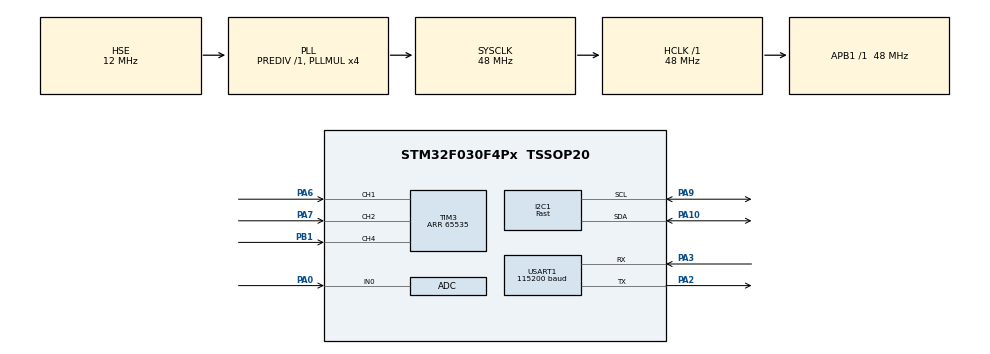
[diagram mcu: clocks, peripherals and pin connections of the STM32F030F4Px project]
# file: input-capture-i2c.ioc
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ADC.SamplingTime=ADC_SAMPLETIME_239CYCLES_5
I2C1.I2C_Speed_Mode=I2C_Fast
I2C1.OwnAddress=4
I2C1.Timing=0x2010091A
Mcu.Family=STM32F0
Mcu.Name=STM32F030F4Px
Mcu.Package=TSSOP20
NVIC.ADC1_IRQn=true\:3\:0\:true\:false\:true
NVIC.I2C1_IRQn=true\:2\:0\:true\:false\:true
NVIC.TIM1_BRK_UP_TRG_COM_IRQn=true\:2\:0\:true\:false\:true
NVIC.TIM3_IRQn=true\:0\:0\:false\:false\:true
NVIC.USART1_IRQn=true\:3\:0\:true\:false\:true
PA0.Mode=IN0
PA0.Signal=ADC_IN0
PA10.GPIO_PuPdOD=GPIO_PULLUP
PA10.Mode=I2C
PA10.Signal=I2C1_SDA
PA13.Mode=Serial_Wire
PA13.Signal=SYS_SWDIO
PA14.Mode=Serial_Wire
PA14.Signal=SYS_SWCLK
PA2.Mode=Asynchronous
PA2.Signal=USART1_TX
PA3.Mode=Asynchronous
PA3.Signal=USART1_RX
PA6.Signal=S_TIM3_CH1
PA7.Signal=S_TIM3_CH2
PA9.GPIO_PuPdOD=GPIO_PULLUP
PA9.Mode=I2C
PA9.Signal=I2C1_SCL
PB1.Signal=S_TIM3_CH4
PF0-OSC_IN.Mode=HSE-External-Clock-Source
PF0-OSC_IN.Signal=RCC_OSC_IN
ProjectManager.HeapSize=0x200
ProjectManager.StackSize=0x400
ProjectManager.TargetToolchain=SW4STM32
RCC.AHBFreq_Value=48000000
RCC.APB1Freq_Value=48000000
RCC.APB1TimFreq_Value=48000000
RCC.HCLKFreq_Value=48000000
RCC.HSE_VALUE=12000000
RCC.HSIState=RCC_HSI_ON
RCC.I2c1ClockSelection=RCC_I2C1CLKSOURCE_SYSCLK
RCC.PLLMUL=RCC_PLL_MUL4
RCC.PLLSourceVirtual=RCC_PLLSOURCE_HSE
RCC.RTCClockSelection=RCC_RTCCLKSOURCE_HSE_DIV32
RCC.SYSCLKFreq_VALUE=48000000
RCC.SYSCLKSource=RCC_SYSCLKSOURCE_PLLCLK
SH.S_TIM3_CH1.0=TIM3_CH1,Input_Capture1_from_TI1
SH.S_TIM3_CH2.0=TIM3_CH2,Input_Capture2_from_TI2
SH.S_TIM3_CH4.0=TIM3_CH4,Input_Capture4_from_TI4
TIM1.Period=65535
TIM3.Channel-Input_Capture2_from_TI2=TIM_CHANNEL_2
TIM3.Channel-Input_Capture4_from_TI4=TIM_CHANNEL_4
TIM3.ICFilter_CH1=3
TIM3.ICFilter_CH2=3
TIM3.ICFilter_CH4=3
TIM3.Period=65535
TIM3.TIM_MasterOutputTrigger=TIM_TRGO_UPDATE
TIM3.TIM_MasterSlaveMode=TIM_MASTERSLAVEMODE_ENABLE
USART1.BaudRate=115200
VP_ADC_TempSens_Input.Mode=IN-TempSens
VP_ADC_Vref_Input.Mode=IN-Vrefint
VP_TIM1_VS_ClockSourceITR.Mode=TriggerSource_ITR2
VP_TIM1_VS_ControllerModeClock.Mode=Clock Mode
VP_TIM3_VS_ClockSourceINT.Mode=Internal
board=input-capture-i2c

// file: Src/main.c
/**
  ******************************************************************************
  * File Name          : main.c
  * Description        : Main program body
  ******************************************************************************
  *
  * COPYRIGHT(c) 2017 STMicroelectronics
  *
  * Redistribution and use in source and binary forms, with or without modification,
  * are permitted provided that the following conditions are met:
  *   1. Redistributions of source code must retain the above copyright notice,
  *      this list of conditions and the following disclaimer.
  *   2. Redistributions in binary form must reproduce the above copyright notice,
  *      this list of conditions and the following disclaimer in the documentation
  *      and/or other materials provided with the distribution.
  *   3. Neither the name of STMicroelectronics nor the names of its contributors
  *      may be used to endorse or promote products derived from this software
  *      without specific prior written permission.
  *
  * THIS SOFTWARE IS PROVIDED BY THE COPYRIGHT HOLDERS AND CONTRIBUTORS "AS IS"
  * AND ANY EXPRESS OR IMPLIED WARRANTIES, INCLUDING, BUT NOT LIMITED TO, THE
  * IMPLIED WARRANTIES OF MERCHANTABILITY AND FITNESS FOR A PARTICULAR PURPOSE ARE
  * DISCLAIMED. IN NO EVENT SHALL THE COPYRIGHT HOLDER OR CONTRIBUTORS BE LIABLE
  * FOR ANY DIRECT, INDIRECT, INCIDENTAL, SPECIAL, EXEMPLARY, OR CONSEQUENTIAL
  * DAMAGES (INCLUDING, BUT NOT LIMITED TO, PROCUREMENT OF SUBSTITUTE GOODS OR
  * SERVICES; LOSS OF USE, DATA, OR PROFITS; OR BUSINESS INTERRUPTION) HOWEVER
  * CAUSED AND ON ANY THEORY OF LIABILITY, WHETHER IN CONTRACT, STRICT LIABILITY,
  * OR TORT (INCLUDING NEGLIGENCE OR OTHERWISE) ARISING IN ANY WAY OUT OF THE USE
  * OF THIS SOFTWARE, EVEN IF ADVISED OF THE POSSIBILITY OF SUCH DAMAGE.
  *
  ******************************************************************************
  */
#include "main.h"
#include "stm32f0xx_hal.h"

/* USER CODE BEGIN Includes */
#include "uart.h"
#include "timer.h"
#include "i2c_slave.h"
#include "adc.h"
/* USER CODE END Includes */

ADC_HandleTypeDef hadc;

I2C_HandleTypeDef hi2c1;

TIM_HandleTypeDef htim1;
TIM_HandleTypeDef htim3;

UART_HandleTypeDef huart1;

/* USER CODE BEGIN PV */
/* Private variables ---------------------------------------------------------*/

/* USER CODE END PV */

void SystemClock_Config(void);
void Error_Handler(void);
static void MX_GPIO_Init(void);
static void MX_TIM1_Init(void);
static void MX_TIM3_Init(void);
static void MX_USART1_UART_Init(void);
static void MX_I2C1_Init(void);
static void MX_ADC_Init(void);

/* USER CODE BEGIN PFP */
/* Private function prototypes -----------------------------------------------*/

/* USER CODE END PFP */

int main(void)
{

  /* MCU Configuration----------------------------------------------------------*/

  /* Reset of all peripherals, Initializes the Flash interface and the Systick. */
  HAL_Init();

  /* Configure the system clock */
  SystemClock_Config();

  /* Initialize all configured peripherals */
  MX_GPIO_Init();
  MX_TIM1_Init();
  MX_TIM3_Init();
  MX_USART1_UART_Init();
  MX_I2C1_Init();
  MX_ADC_Init();

  /* USER CODE BEGIN 2 */
  HAL_ADCEx_Calibration_Start(&hadc);
  i2c_slave_start();
  timer_start();
  /* USER CODE END 2 */

  /* Infinite loop */
  while (1)
  {

  /* USER CODE BEGIN 3 */

    /* debugging code
    print_timer_status();
    i2c_show_data();
     */
    adc_poll();
    HAL_Delay(100);
  }
  /* USER CODE END 3 */

}

/** System Clock Configuration
*/
void SystemClock_Config(void)
{

  RCC_OscInitTypeDef RCC_OscInitStruct;
  RCC_ClkInitTypeDef RCC_ClkInitStruct;
  RCC_PeriphCLKInitTypeDef PeriphClkInit;

    /**Initializes the CPU, AHB and APB busses clocks
    */
  RCC_OscInitStruct.OscillatorType = RCC_OSCILLATORTYPE_HSI14|RCC_OSCILLATORTYPE_HSE;
  RCC_OscInitStruct.HSEState = RCC_HSE_BYPASS;
  RCC_OscInitStruct.HSIState = RCC_HSI_ON;
  RCC_OscInitStruct.HSI14State = RCC_HSI14_ON;
  RCC_OscInitStruct.HSI14CalibrationValue = 16;
  RCC_OscInitStruct.PLL.PLLState = RCC_PLL_ON;
  RCC_OscInitStruct.PLL.PLLSource = RCC_PLLSOURCE_HSE;
  RCC_OscInitStruct.PLL.PLLMUL = RCC_PLL_MUL4;
  RCC_OscInitStruct.PLL.PREDIV = RCC_PREDIV_DIV1;
  if (HAL_RCC_OscConfig(&RCC_OscInitStruct) != HAL_OK)
  {
    Error_Handler();
  }

    /**Initializes the CPU, AHB and APB busses clocks
    */
  RCC_ClkInitStruct.ClockType = RCC_CLOCKTYPE_HCLK|RCC_CLOCKTYPE_SYSCLK
                              |RCC_CLOCKTYPE_PCLK1;
  RCC_ClkInitStruct.SYSCLKSource = RCC_SYSCLKSOURCE_PLLCLK;
  RCC_ClkInitStruct.AHBCLKDivider = RCC_SYSCLK_DIV1;
  RCC_ClkInitStruct.APB1CLKDivider = RCC_HCLK_DIV1;

  if (HAL_RCC_ClockConfig(&RCC_ClkInitStruct, FLASH_LATENCY_1) != HAL_OK)
  {
    Error_Handler();
  }

  PeriphClkInit.PeriphClockSelection = RCC_PERIPHCLK_USART1|RCC_PERIPHCLK_I2C1;
  PeriphClkInit.Usart1ClockSelection = RCC_USART1CLKSOURCE_PCLK1;
  PeriphClkInit.I2c1ClockSelection = RCC_I2C1CLKSOURCE_SYSCLK;
  if (HAL_RCCEx_PeriphCLKConfig(&PeriphClkInit) != HAL_OK)
  {
    Error_Handler();
  }

    /**Configure the Systick interrupt time
    */
  HAL_SYSTICK_Config(HAL_RCC_GetHCLKFreq()/1000);

    /**Configure the Systick
    */
  HAL_SYSTICK_CLKSourceConfig(SYSTICK_CLKSOURCE_HCLK);

  /* SysTick_IRQn interrupt configuration */
  HAL_NVIC_SetPriority(SysTick_IRQn, 0, 0);
}

/* ADC init function */
static void MX_ADC_Init(void)
{

  ADC_ChannelConfTypeDef sConfig;

    /**Configure the global features of the ADC (Clock, Resolution, Data Alignment and number of conversion)
    */
  hadc.Instance = ADC1;
  hadc.Init.ClockPrescaler = ADC_CLOCK_ASYNC_DIV1;
  hadc.Init.Resolution = ADC_RESOLUTION_12B;
  hadc.Init.DataAlign = ADC_DATAALIGN_RIGHT;
  hadc.Init.ScanConvMode = ADC_SCAN_DIRECTION_FORWARD;
  hadc.Init.EOCSelection = ADC_EOC_SINGLE_CONV;
  hadc.Init.LowPowerAutoWait = ENABLE;
  hadc.Init.LowPowerAutoPowerOff = DISABLE;
  hadc.Init.ContinuousConvMode = DISABLE;
  hadc.Init.DiscontinuousConvMode = DISABLE;
  hadc.Init.ExternalTrigConv = ADC_SOFTWARE_START;
  hadc.Init.ExternalTrigConvEdge = ADC_EXTERNALTRIGCONVEDGE_NONE;
  hadc.Init.DMAContinuousRequests = DISABLE;
  hadc.Init.Overrun = ADC_OVR_DATA_PRESERVED;
  if (HAL_ADC_Init(&hadc) != HAL_OK)
  {
    Error_Handler();
  }

    /**Configure for the selected ADC regular channel to be converted.
    */
  sConfig.Channel = ADC_CHANNEL_0;
  sConfig.Rank = ADC_RANK_CHANNEL_NUMBER;
  sConfig.SamplingTime = ADC_SAMPLETIME_239CYCLES_5;
  if (HAL_ADC_ConfigChannel(&hadc, &sConfig) != HAL_OK)
  {
    Error_Handler();
  }

    /**Configure for the selected ADC regular channel to be converted.
    */
  sConfig.Channel = ADC_CHANNEL_TEMPSENSOR;
  if (HAL_ADC_ConfigChannel(&hadc, &sConfig) != HAL_OK)
  {
    Error_Handler();
  }

    /**Configure for the selected ADC regular channel to be converted.
    */
  sConfig.Channel = ADC_CHANNEL_VREFINT;
  if (HAL_ADC_ConfigChannel(&hadc, &sConfig) != HAL_OK)
  {
    Error_Handler();
  }
}

/* I2C1 init function */
static void MX_I2C1_Init(void)
{

  hi2c1.Instance = I2C1;
  hi2c1.Init.Timing = 0x2010091A;
  hi2c1.Init.OwnAddress1 = 8;
  hi2c1.Init.AddressingMode = I2C_ADDRESSINGMODE_7BIT;
  hi2c1.Init.DualAddressMode = I2C_DUALADDRESS_DISABLE;
  hi2c1.Init.OwnAddress2 = 0;
  hi2c1.Init.OwnAddress2Masks = I2C_OA2_NOMASK;
  hi2c1.Init.GeneralCallMode = I2C_GENERALCALL_DISABLE;
  hi2c1.Init.NoStretchMode = I2C_NOSTRETCH_DISABLE;
  if (HAL_I2C_Init(&hi2c1) != HAL_OK)
  {
    Error_Handler();
  }

    /**Configure Analogue filter
    */
  if (HAL_I2CEx_ConfigAnalogFilter(&hi2c1, I2C_ANALOGFILTER_ENABLE) != HAL_OK)
  {
    Error_Handler();
  }

}

/* TIM1 init function */
static void MX_TIM1_Init(void)
{

  TIM_SlaveConfigTypeDef sSlaveConfig;
  TIM_MasterConfigTypeDef sMasterConfig;

  htim1.Instance = TIM1;
  htim1.Init.Prescaler = 0;
  htim1.Init.CounterMode = TIM_COUNTERMODE_UP;
  htim1.Init.Period = 65535;
  htim1.Init.ClockDivision = TIM_CLOCKDIVISION_DIV1;
  htim1.Init.RepetitionCounter = 0;
  htim1.Init.AutoReloadPreload = TIM_AUTORELOAD_PRELOAD_DISABLE;
  if (HAL_TIM_Base_Init(&htim1) != HAL_OK)
  {
    Error_Handler();
  }

  sSlaveConfig.SlaveMode = TIM_SLAVEMODE_EXTERNAL1;
  sSlaveConfig.InputTrigger = TIM_TS_ITR2;
  if (HAL_TIM_SlaveConfigSynchronization(&htim1, &sSlaveConfig) != HAL_OK)
  {
    Error_Handler();
  }

  sMasterConfig.MasterOutputTrigger = TIM_TRGO_RESET;
  sMasterConfig.MasterSlaveMode = TIM_MASTERSLAVEMODE_DISABLE;
  if (HAL_TIMEx_MasterConfigSynchronization(&htim1, &sMasterConfig) != HAL_OK)
  {
    Error_Handler();
  }

}

/* TIM3 init function */
static void MX_TIM3_Init(void)
{

  TIM_ClockConfigTypeDef sClockSourceConfig;
  TIM_MasterConfigTypeDef sMasterConfig;
  TIM_IC_InitTypeDef sConfigIC;

  htim3.Instance = TIM3;
  htim3.Init.Prescaler = 0;
  htim3.Init.CounterMode = TIM_COUNTERMODE_UP;
  htim3.Init.Period = 65535;
  htim3.Init.ClockDivision = TIM_CLOCKDIVISION_DIV1;
  htim3.Init.AutoReloadPreload = TIM_AUTORELOAD_PRELOAD_DISABLE;
  if (HAL_TIM_Base_Init(&htim3) != HAL_OK)
  {
    Error_Handler();
  }

  sClockSourceConfig.ClockSource = TIM_CLOCKSOURCE_INTERNAL;
  if (HAL_TIM_ConfigClockSource(&htim3, &sClockSourceConfig) != HAL_OK)
  {
    Error_Handler();
  }

  if (HAL_TIM_IC_Init(&htim3) != HAL_OK)
  {
    Error_Handler();
  }

  sMasterConfig.MasterOutputTrigger = TIM_TRGO_UPDATE;
  sMasterConfig.MasterSlaveMode = TIM_MASTERSLAVEMODE_ENABLE;
  if (HAL_TIMEx_MasterConfigSynchronization(&htim3, &sMasterConfig) != HAL_OK)
  {
    Error_Handler();
  }

  sConfigIC.ICPolarity = TIM_INPUTCHANNELPOLARITY_RISING;
  sConfigIC.ICSelection = TIM_ICSELECTION_DIRECTTI;
  sConfigIC.ICPrescaler = TIM_ICPSC_DIV1;
  sConfigIC.ICFilter = 3;
  if (HAL_TIM_IC_ConfigChannel(&htim3, &sConfigIC, TIM_CHANNEL_1) != HAL_OK)
  {
    Error_Handler();
  }

  if (HAL_TIM_IC_ConfigChannel(&htim3, &sConfigIC, TIM_CHANNEL_2) != HAL_OK)
  {
    Error_Handler();
  }

  if (HAL_TIM_IC_ConfigChannel(&htim3, &sConfigIC, TIM_CHANNEL_4) != HAL_OK)
  {
    Error_Handler();
  }

}

/* USART1 init function */
static void MX_USART1_UART_Init(void)
{

  huart1.Instance = USART1;
  huart1.Init.BaudRate = 115200;
  huart1.Init.WordLength = UART_WORDLENGTH_8B;
  huart1.Init.StopBits = UART_STOPBITS_1;
  huart1.Init.Parity = UART_PARITY_NONE;
  huart1.Init.Mode = UART_MODE_TX_RX;
  huart1.Init.HwFlowCtl = UART_HWCONTROL_NONE;
  huart1.Init.OverSampling = UART_OVERSAMPLING_16;
  huart1.Init.OneBitSampling = UART_ONE_BIT_SAMPLE_DISABLE;
  huart1.AdvancedInit.AdvFeatureInit = UART_ADVFEATURE_NO_INIT;
  if (HAL_UART_Init(&huart1) != HAL_OK)
  {
    Error_Handler();
  }

}

/** Configure pins as
        * Analog
        * Input
        * Output
        * EVENT_OUT
        * EXTI
*/
static void MX_GPIO_Init(void)
{

  /* GPIO Ports Clock Enable */
  __HAL_RCC_GPIOF_CLK_ENABLE();
  __HAL_RCC_GPIOA_CLK_ENABLE();
  __HAL_RCC_GPIOB_CLK_ENABLE();

}

void Error_Handler(void)
{
  while(1)
  {
  }
}

/************************ (C) COPYRIGHT STMicroelectronics *****END OF FILE****/
